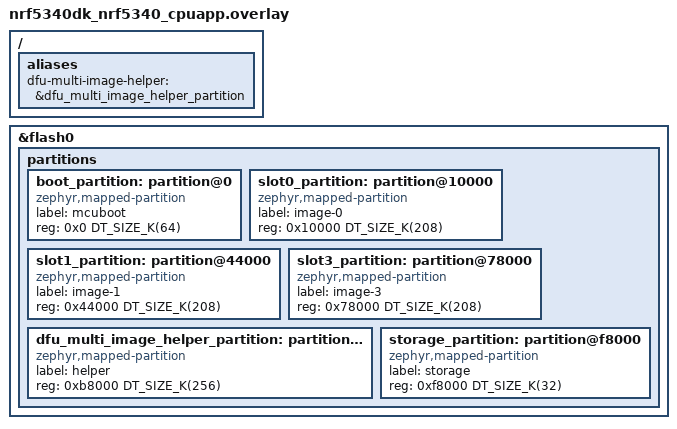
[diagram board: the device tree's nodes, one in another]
/*
 * Copyright (c) 2026 Nordic Semiconductor ASA
 *
 * SPDX-License-Identifier: LicenseRef-Nordic-5-Clause
 */

/delete-node/ &boot_partition;
/delete-node/ &slot0_partition;
/delete-node/ &slot1_partition;
/delete-node/ &storage_partition;

/ {
	aliases {
		dfu-multi-image-helper = &dfu_multi_image_helper_partition;
	};
};

&flash0 {
	partitions {
		ranges;
		#address-cells = <1>;
		#size-cells = <1>;

		boot_partition: partition@0 {
			compatible = "zephyr,mapped-partition";
			label = "mcuboot";
			reg = <0x0 DT_SIZE_K(64)>;
		};

		slot0_partition: partition@10000 {
			compatible = "zephyr,mapped-partition";
			label = "image-0";
			reg = <0x10000 DT_SIZE_K(208)>;
		};

		slot1_partition: partition@44000 {
			compatible = "zephyr,mapped-partition";
			label = "image-1";
			reg = <0x44000 DT_SIZE_K(208)>;
		};

		slot3_partition: partition@78000 {
			compatible = "zephyr,mapped-partition";
			label = "image-3";
			reg = <0x78000 DT_SIZE_K(208)>;
		};

		dfu_multi_image_helper_partition: partition@b8000 {
			compatible = "zephyr,mapped-partition";
			label = "helper";
			reg = <0xb8000 DT_SIZE_K(256)>;
		};

		storage_partition: partition@f8000 {
			compatible = "zephyr,mapped-partition";
			label = "storage";
			reg = <0xf8000 DT_SIZE_K(32)>;
		};
	};
};
